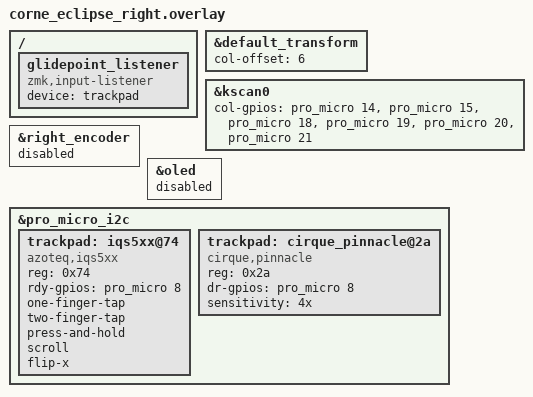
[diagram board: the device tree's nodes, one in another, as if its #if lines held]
/*
 * Copyright (c) 2020 Pete Johanson
 *
 * SPDX-License-Identifier: MIT
 */

#include "corne_eclipse.dtsi"

&default_transform {
    col-offset = <6>;
};

/*
&five_column_transform {
    col-offset = <6>;
};
*/

&kscan0 {
    col-gpios
        = <&pro_micro 14 GPIO_ACTIVE_HIGH>
        , <&pro_micro 15 GPIO_ACTIVE_HIGH>
        , <&pro_micro 18 GPIO_ACTIVE_HIGH>
        , <&pro_micro 19 GPIO_ACTIVE_HIGH>
        , <&pro_micro 20 GPIO_ACTIVE_HIGH>
        , <&pro_micro 21 GPIO_ACTIVE_HIGH>
        ;
};

/* Compatibility alias: pre-existing builds used plain USE_TRACKPAD. */
#if defined(USE_TRACKPAD) && !defined(USE_TRACKPAD_AZOTEQ) && !defined(USE_TRACKPAD_CIRQUE)
#define USE_TRACKPAD_AZOTEQ
#endif

#if defined(USE_TRACKPAD_AZOTEQ) || defined(USE_TRACKPAD_CIRQUE)

&right_encoder {
    status = "disabled";
};

&oled {
    status = "disabled";
};

#else

&right_encoder {
    status = "okay";
};

#endif

#ifdef USE_TRACKPAD_AZOTEQ
&pro_micro_i2c {
    trackpad: iqs5xx@74 {
        compatible = "azoteq,iqs5xx";
        reg = <0x74>;
        rdy-gpios = <&pro_micro 8 GPIO_ACTIVE_HIGH>;
        one-finger-tap;
        two-finger-tap;
        press-and-hold;
        scroll;
        flip-x;
    };
};
#endif

#ifdef USE_TRACKPAD_CIRQUE
&pro_micro_i2c {
    trackpad: cirque_pinnacle@2a {
        compatible = "cirque,pinnacle";
        reg = <0x2a>; /* 0x2c if the module's R1 jumper is bridged */
        dr-gpios = <&pro_micro 8 GPIO_ACTIVE_HIGH>;
        sensitivity = "4x";
    };
};

/ {
    glidepoint_listener: glidepoint_listener {
        compatible = "zmk,input-listener";
        device = <&trackpad>;
        /* Tune orientation after first flash if X/Y feel inverted:
         * input-processors = <&zip_xy_transform (INPUT_TRANSFORM_X_INVERT)>;
         */
    };
};
#endif
